# RP2350 register map
Vendor: Raspberry Pi; File version: 0.1
CPU: CM33 r1p0, little endian, MPU, FPU, VTOR, 4 interrupt priority bits, 54 interrupts, 8 SAU regions
Registers are 32-bit, read-write, reset 0x0 unless marked. A register's access mark holds for its fields unless they carry their own. Offsets are from the block's base; [hi:lo] are bit positions; lines under a group give offsets from that group.

## RISCV_DM_DUMMY_ADDRESS_FIXME — RISC-V Debug module registers (Hazard3 subset only). Read-only information fields (such as dmstatus.version) are listed here with the values they have on the RP2350 instantiation of Hazard3.
Base 0x4014A000
0x10 DATA0 — data0 through data11 are basic read/write registers that may be read or changed by abstract commands. abstractcs.datacount indicates how many of them are implemented, starting at data0, counting up. . Accessing these registers while an abstract command is executing causes abstractcs.cmderr to be set to 1 (busy) if it is 0. . Attempts to write them while abstractcs.busy is set does not change their value. . The values in these registers may not be preserved after an abstract command is executed. The only guarantees on their contents are the ones offered by the command in question. If the command fails, no assumptions can be made about the contents of these registers. (Note: Hazard3 implements data0 only.)
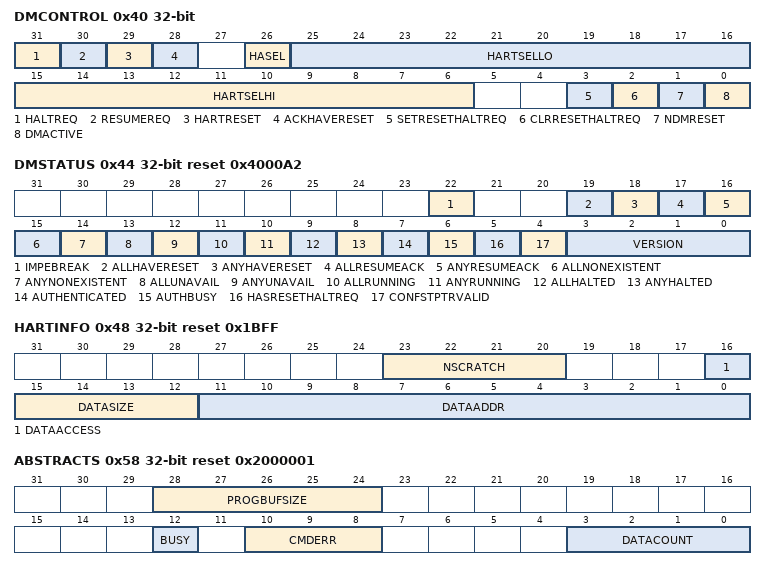
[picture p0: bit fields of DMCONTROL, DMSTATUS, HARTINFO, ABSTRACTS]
0x40 DMCONTROL access per field — This register controls the overall Debug Module as well as the currently selected harts, as defined in hasel.
  [31] HALTREQ wo — Writing 0 clears the halt request bit for all currently selected harts. This may cancel outstanding halt requests for those harts. . Writing 1 sets the halt request bit for all currently selected harts. Running harts will halt whenever their halt request bit is set. . Writes apply to the new value of hartsel and hasel.
  [30] RESUMEREQ rw write-clears — Writing 1 causes the currently selected harts to resume once, if they are halted when the write occurs. It also clears the resume ack bit for those harts. resumereq is ignored if haltreq is set. . Writes apply to the new value of hartsel and hasel.
  [29] HARTRESET rw — This optional field writes the reset bit for all the currently selected harts. To perform a reset the debugger writes 1, and then writes 0 to deassert the reset signal. . While this bit is 1, the debugger must not change which harts are selected. . Writes apply to the new value of hartsel and hasel. (The exact behaviour of this field is implementation-defined: on RP2350 it (triggers a local reset of the selected core(s) only.)
  [28] ACKHAVERESET rw write-clears — 0: No effect. . 1: Clears havereset for any selected harts. . Writes apply to the new value of hartsel and hasel.
  [26] HASEL rw — Selects the definition of currently selected harts. . 0: There is a single currently selected hart, that is selected by hartsel. . 1: There may be multiple currently selected harts – the hart selected by hartsel, plus those selected by the hart array mask register. . Hazard3 does support the hart array mask.
  [25:16] HARTSELLO rw — The low 10 bits of hartsel: the DM-specific index of the hart to select. This hart is always part of the currently selected harts. . On RP2350, since there are only two cores (with one hart each), only the least-significant bit is writable. The others are tied to 0.
  [15:6] HARTSELHI rw — The high 10 bits of hartsel: the DM-specific index of the hart to select. This hart is always part of the currently selected harts. . On Hazard3 this field is always tied to all-zeroes.
  [3] SETRESETHALTREQ rw write-clears — This optional field writes the halt-on-reset request bit for all currently selected harts, unless clrresethaltreq is simultaneously set to 1. . When set to 1, each selected hart will halt upon the next deassertion of its reset. The halt-on-reset request bit is not automatically cleared. The debugger must write to clrresethaltreq to clear it. . Writes apply to the new value of hartsel and hasel.
  [2] CLRRESETHALTREQ rw write-clears — This optional field clears the halt-on-reset request bit for all currently selected harts. . Writes apply to the new value of hartsel and hasel.
  [1] NDMRESET rw — This bit controls the reset signal from the DM to the rest of the system. The signal should reset every part of the system, including every hart, except for the DM and any logic required to access the DM. To perform a system reset the debugger writes 1, and then writes 0 to deassert the reset. . On RP2350 this performs a cold reset, the equivalent of a watchdog reset with all WDSEL bits set. This includes both cores and all peripherals.
  [0] DMACTIVE rw — This bit serves as a reset signal for the Debug Module itself. . 0: The module’s state, including authentication mechanism, takes its reset values (the dmactive bit is the only bit which can be written to something other than its reset value). . 1: The module functions normally. . No other mechanism should exist that may result in resetting the Debug Module after power up, with the possible (but not recommended) exception of a global reset signal that resets the entire platform. (On RP2350, the Debug Module is reset by a power-on reset, a brownout reset, the RUN pin, and a rescue reset.) . A debugger may pulse this bit low to get the Debug Module into a known state.
0x44 DMSTATUS ro reset 0x4000A2 — This register reports status for the overall Debug Module as well as the currently selected harts, as defined in hasel. Its address will not change in the future, because it contains version. . This entire register is read-only.
  [22] IMPEBREAK — If 1, then there is an implicit ebreak instruction at the non-existent word immediately after the Program Buffer. This saves the debugger from having to write the ebreak itself, and allows the Program Buffer to be one word smaller.
  [19] ALLHAVERESET — This field is 1 when all currently selected harts have been reset and reset has not been acknowledged for any of them.
  [18] ANYHAVERESET — This field is 1 when at least one currently selected hart has been reset and reset has not been acknowledged for that hart.
  [17] ALLRESUMEACK — This field is 1 when all currently selected harts have acknowledged their last resume request.
  [16] ANYRESUMEACK — This field is 1 when any currently selected hart has acknowledged its last resume request.
  [15] ALLNONEXISTENT — This field is 1 when all currently selected harts do not exist on this platform.
  [14] ANYNONEXISTENT — This field is 1 when any currently selected hart does not exist in this platform.
  [13] ALLUNAVAIL — This field is 1 when all currently selected harts are unavailable.
  [12] ANYUNAVAIL — This field is 1 when any currently selected hart is unavailable.
  [11] ALLRUNNING — This field is 1 when all currently selected harts are running.
  [10] ANYRUNNING — This field is 1 when any currently selected hart is running.
  [9] ALLHALTED — This field is 1 when all currently selected harts are halted.
  [8] ANYHALTED — This field is 1 when any currently selected hart is halted.
  [7] AUTHENTICATED — 0: Authentication is required before using the DM. . 1: The authentication check has passed. . On components that don’t implement authentication, this bit must be preset as 1. (Note: the version of Hazard3 on RP2350 does not implement authentication.)
  [6] AUTHBUSY — 0: The authentication module is ready to process the next read/write to authdata. . 1: The authentication module is busy. Accessing authdata results in unspecified behavior. authbusy only becomes set in immediate response to an access to authdata.
  [5] HASRESETHALTREQ — 1 if this Debug Module supports halt-on-reset functionality controllable by the setresethaltreq and clrresethaltreq bits. 0 otherwise.
  [4] CONFSTPTRVALID — 0: confstrptr0–confstrptr3 hold information which is not relevant to the configuration string. . 1: confstrptr0–confstrptr3 hold the address of the configuration string.
  [3:0] VERSION — 0: There is no Debug Module present. 1: There is a Debug Module and it conforms to version 0.11 of the RISC-V debug specification. . 2: There is a Debug Module and it conforms to version 0.13 of the RISC-V debug specification. . 15: There is a Debug Module but it does not con- form to any available version of the RISC-V debug spec.
0x48 HARTINFO access per field reset 0x1BFF — This register gives information about the hart currently selected by hartsel. . This entire register is read-only.
  [23:20] NSCRATCH ro — Number of dscratch registers available for the debugger to use during program buffer execution, starting from dscratch0. The debugger can make no assumptions about the contents of these registers between commands.
  [16] DATAACCESS ro — 0: The data registers are shadowed in the hart by CSRs. Each CSR is DXLEN bits in size, and corresponds to a single argument. . 1: The data registers are shadowed in the hart’s memory map. Each register takes up 4 bytes in the memory map.
  [15:12] DATASIZE rw — If dataaccess is 0: Number of CSRs dedicated to shadowing the data registers. . If dataaccess is 1: Number of 32-bit words in the memory map dedicated to shadowing the data registers.
  [11:0] DATAADDR rw — If dataaccess is 0: The number of the first CSR dedicated to shadowing the data registers. . If dataaccess is 1: Signed address of RAM where the data registers are shadowed, to be used to access relative to zero . On Hazard3 this indicates the single data register mapped as dmdata0. There is actually only a single shared register, internal to the Debug Module, and mirrored in each core's CSR space.
0x4C HALTSUM1 ro — Each bit in this read-only register indicates whether any of a group of harts is halted or not. Unavailable/nonexistent harts are not considered to be halted. . Each bit in haltsum1 is an OR reduction of 32 bits' worth of haltsum0. On RP2350, only the LSB is implemented.
  [0] HALTSUM1
0x50 HAWINDOWSEL — This register selects which of the 32-bit portion of the hart array mask register is accessible in hawindow.
  [14:0] HAWINDOWSEL — On Hazard3 this register is entirely hardwired to 0.
0x54 HAWINDOW — This register provides R/W access to a 32-bit portion of the hart array mask register. The position of the window is determined by hawindowsel. I.e. bit 0 refers to hart hawindowsel ∗ 32, while bit 31 refers to hart hawindowsel ∗ 32 + 31. . On RP2350 only the two least-significant bits of this register are implemented, since there are only two cores. This is still useful to run/halt/reset both cores exactly simultaneously.
  [1:0] MASKDATA
0x58 ABSTRACTS access per field reset 0x2000001 — Abstract Control and Status. Writing this register while an abstract command is executing causes cmderr to be set to 1 (busy) if it is 0.
  [28:24] PROGBUFSIZE rw — Size of the Program Buffer, in 32-bit words.
  [12] BUSY rw — 1: An abstract command is currently being executed. . This bit is set as soon as command is written, and is not cleared until that command has completed.
  [10:8] CMDERR rw write-1-clears — Gets set if an abstract command fails. The bits in this field remain set until they are cleared by writing 1 to them. No abstract command is started until the value is reset to 0. . This field only contains a valid value if busy is 0. . 0 (none): No error. . 1 (busy): An abstract command was executing while command, abstractcs, or abstractauto was written, or when one of the data or progbuf registers was read or written. This status is only written if cmderr contains 0. . 2 (not supported): The requested command is not supported, regardless of whether the hart is running or not. . 3 (exception): An exception occurred while executing the command (e.g. while executing the Program Buffer). . 4 (halt/resume): The abstract command couldn’t execute because the hart wasn’t in the required state (running/halted), or unavailable. . 5 (bus): The abstract command failed due to a bus error (e.g. alignment, access size, or timeout). . 7 (other): The command failed for another reason. . Note: Hazard3 does not set values 5 or 7. Load/store instructions in the program buffer raise an exception when they encounter a bus fault, setting cmderr=3.
  [3:0] DATACOUNT ro — Number of data registers that are implemented as part of the abstract command interface.
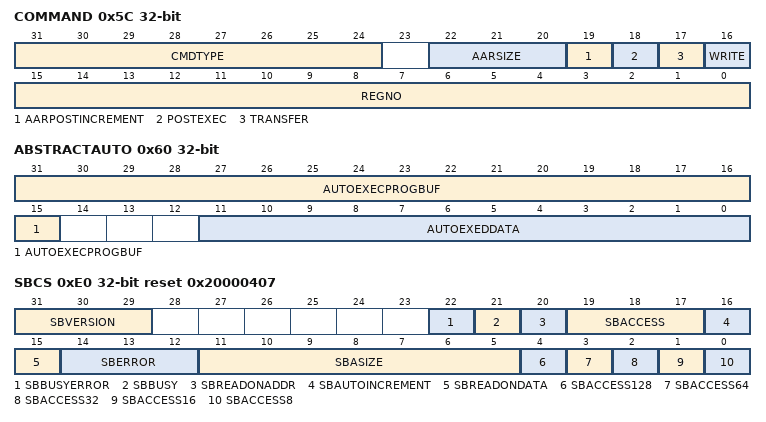
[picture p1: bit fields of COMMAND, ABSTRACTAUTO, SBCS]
0x5C COMMAND wo — Writes to this register cause the corresponding abstract command to be executed. . Writing this register while an abstract command is executing causes cmderr to be set to 1 (busy) if it is 0. . If cmderr is non-zero, writes to this register are ignored.
  [31:24] CMDTYPE — On Hazard3 this field must be 0 (Access Register)
  [22:20] AARSIZE — On Hazard3 this field must be 2 (32-bit register access)
  [19] AARPOSTINCREMENT — On Hazard3 this field must be 0 (no post-increment of regno)
  [18] POSTEXEC — 0: No effect. . 1: Execute the program in the Program Buffer exactly once after performing the transfer, if any.
  [17] TRANSFER — 0: Don’t do the operation specified by write. . 1: Do the operation specified by write. . This bit can be used to just execute the Program Buffer without having to worry about placing valid values into aarsize or regno.
  [16] WRITE — When transfer is set: . 0: Copy data from the specified register into data0. . 1: Copy data from data0 into the specified register.
  [15:0] REGNO — Number of the register to access. . On Hazard3 this must be in the range 0x1000 through 0x101f inclusive, referring to GPRs x0 through x31.
0x60 ABSTRACTAUTO — Abstract Command Autoexec. Writing this register while an abstract command is executing causes cmderr to be set to 1 (busy) if it is 0.
  [31:15] AUTOEXECPROGBUF — When a bit in this field is 1, read or write accesses to the corresponding progbuf word cause the command in command to be executed again. . Hazard3 implements only the two least-significant bits of this field (for the two-entry progbuf)
  [11:0] AUTOEXEDDATA — When a bit in this field is 1, read or write accesses to the corresponding data word cause the command in command to be executed again. . Hazard3 implements only the least-significant bit of this field.
0x74 NEXTDM ro — If there is more than one DM accessible on this DMI, this register contains the base address of thenext one in the chain, or 0 if this is the last one in the chain.
0x80 PROGBUF0 — progbuf0 through progbuf15 provide read/write access to the program buffer. abstractcs.progbufsize indicates how many of them are implemented starting at progbuf0, counting up. (Hazard3 implements a 2-word program buffer.)
0x84 PROGBUF1 — progbuf0 through progbuf15 provide read/write access to the program buffer. abstractcs.progbufsize indicates how many of them are implemented starting at progbuf0, counting up. (Hazard3 implements a 2-word program buffer.)
0xE0 SBCS access per field reset 0x20000407 — System Bus Access Control and Status
  [31:29] SBVERSION ro — 1: The System Bus interface conforms to version 0.13.2 of the RISC-V debug spec.
  [22] SBBUSYERROR rw write-1-clears — Set when the debugger attempts to read data while a read is in progress, or when the debugger initiates a new access while one is already in progress (while sbbusy is set). It remains set until it’s explicitly cleared by the debugger. . While this field is set, no more system bus accesses can be initiated by the Debug Module.
  [21] SBBUSY ro — When 1, indicates the system bus master is busy. (Whether the system bus itself is busy is related, but not the same thing.) This bit goes high immediately when a read or write is requested for any reason, and does not go low until the access is fully completed. . Writes to sbcs while sbbusy is high result in undefined behavior. A debugger must not write to sbcs until it reads sbbusy as 0.
  [20] SBREADONADDR rw — When 1, every write to sbaddress0 automatically triggers a system bus read at the new address.
  [19:17] SBACCESS rw — Select the access size to use for system bus accesses. . 0: 8-bit . 1: 16-bit . 2: 32-bit . 3: 64-bit . 4: 128-bit . If sbaccess has an unsupported value when the DM starts a bus access, the access is not per formed and sberror is set to 4. (On Hazard3 the supported values are 8-bit, 16-bit and 32-bit.)
  [16] SBAUTOINCREMENT rw — When 1, sbaddress is incremented by the access size (in bytes) selected in sbaccess after every system bus access.
  [15] SBREADONDATA rw — When 1, every read from sbdata0 automatically triggers a system bus read at the (possibly auto- incremented) address.
  [14:12] SBERROR rw write-1-clears — When the Debug Module’s system bus master encounters an error, this field gets set. The bits in this field remain set until they are cleared by writing 1 to them. While this field is non-zero, no more system bus accesses can be initiated by the Debug Module. . An implementation may report “Other” (7) for any error condition. (Hazard3 does not use this value for any errors.) . 0: There was no bus error. . 1: There was a timeout. . 2: A bad address was accessed. . 3: There was an alignment error. . 4: An access of unsupported size was requested. . 7: Other. . Hazard3 raises an alignment error for any non-naturally-aligned bus transfer which would otherwise be a valid transfer.
  [11:5] SBASIZE ro — Width of system bus addresses in bits. (0 indicates there is no bus access support.)
  [4] SBACCESS128 ro — 1 when 128-bit system bus accesses are supported.
  [3] SBACCESS64 ro — 1 when 64-bit system bus accesses are supported.
  [2] SBACCESS32 ro — 1 when 32-bit system bus accesses are supported.
  [1] SBACCESS16 ro — 1 when 16-bit system bus accesses are supported.
  [0] SBACCESS8 ro — 1 when 8-bit system bus accesses are supported.
0xE4 SBADDRESS0 — System Bus Address 31:0 . When the system bus master is busy, writes to this register will set sbbusyerror and don’t do anything else. . If sberror is 0, sbbusyerror is 0, and sbreadonaddr is set then writes to this register start the following: . 1. Set sbbusy. . 2. Perform a bus read from the new value of sbaddress. . 3. If the read succeeded and sbautoincrement is set, increment sbaddress. . 4. Clear sbbusy.
  [31:0] ADDRESS — Accesses bits 31:0 of the physical address in sbaddress.
0xF0 SBDATA0 — System Bus Data 31:0 . Any successful system bus read updates sbdata. If the width of the read access is less than the width of sbdata, the contents of the remaining high bits may take on any value. . If sberror or sbbusyerror both aren’t 0 then accesses do nothing. . If the bus master is busy then accesses set sbbusyerror, and don’t do anything else. Writes to this register start the following: . 1. Set sbbusy. . 2. Perform a bus write of the new value of sbdata to sbaddress. . 3. If the write succeeded and sbautoincrement is set, increment sbaddress. . 4. Clear sbbusy. . Reads from this register start the following: . 1. “Return” the data. . 2. Set sbbusy. . 3. If sbreadondata is set, perform a system bus read from the address contained in sbaddress, placing the result in sbdata. . 4. If the read was successful, and sbautoincrement is set, increment sbaddress. . 5. Clear sbbusy.
  [31:0] DATA
0x100 HALTSUM0 ro — Each bit in this read-only register indicates whether one specific hart is halted or not. Unavailable/nonexistent harts are not considered to be halted. . On RP2350, only the two LSBs of this register are implemented, one for each core/hart. . This entire register is read-only.
